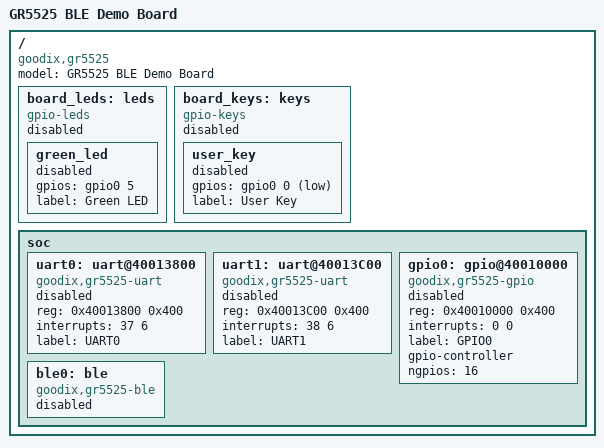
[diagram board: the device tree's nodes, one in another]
/dts-v1/;

#include <arm/goodix/gr5525x.dtsi>
#include <dt-bindings/gpio/gpio.h>

/ {
    compatible = "goodix,gr5525";
    model = "GR5525 BLE Demo Board";

    board_leds: leds {
        status = "disabled";
        compatible = "gpio-leds";
        green_led: green_led {
            status = "disabled";
            gpios = <&gpio0 5 0>;
            label = "Green LED";
        };
    };

    board_keys: keys {
        status = "disabled";
        compatible = "gpio-keys";
        user_key: user_key {
            status = "disabled";
            gpios = <&gpio0 0 (GPIO_ACTIVE_LOW | GPIO_PULL_UP)>;
            label = "User Key";
        };
    };

    soc {
        uart0: uart@40013800 {
            status = "disabled";
            compatible = "goodix,gr5525-uart";
            reg = <0x40013800 0x400>;
            interrupts = <37 6>;
            interrupt-names = "global";
            label = "UART0";
        };

        uart1: uart@40013C00 {
            status = "disabled";
            compatible = "goodix,gr5525-uart";
            reg = <0x40013C00 0x400>;
            interrupts = <38 6>;
            interrupt-names = "global";
            label = "UART1";
        };

        gpio0: gpio@40010000 {
            status = "disabled";
            compatible = "goodix,gr5525-gpio";
            reg = <0x40010000 0x400>;
            interrupts = <0 0>;
            label = "GPIO0";
            gpio-controller;
            #gpio-cells = <2>;
            ngpios = <16>;
        };

        ble0: ble {
            status = "disabled";
            compatible = "goodix,gr5525-ble";
        };
    };
};
